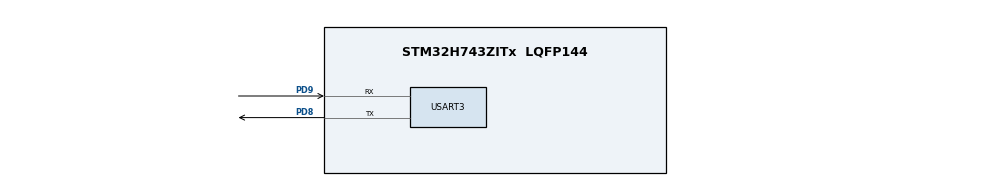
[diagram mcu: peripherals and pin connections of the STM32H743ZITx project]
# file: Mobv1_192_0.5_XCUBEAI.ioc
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CORTEX_M7.CPU_DCache=Enabled
CORTEX_M7.CPU_ICache=Enabled
Mcu.Family=STM32H7
Mcu.Name=STM32H743ZITx
Mcu.Package=LQFP144
NVIC.PriorityGroup=NVIC_PRIORITYGROUP_4
PD8.Mode=Asynchronous
PD8.Signal=USART3_TX
PD9.Mode=Asynchronous
PD9.Signal=USART3_RX
PH0-OSC_IN\ (PH0).Mode=HSE-External-Clock-Source
PH0-OSC_IN\ (PH0).Signal=RCC_OSC_IN
ProjectManager.HeapSize=0x800
ProjectManager.StackSize=0x800
ProjectManager.TargetToolchain=STM32CubeIDE
RCC.ADCFreq_Value=16125000
RCC.APB1CLKDivider=RCC_HCLK_DIV4
RCC.APB1Freq_Value=120000000
RCC.APB2CLKDivider=RCC_HCLK_DIV2
RCC.APB2Freq_Value=120000000
RCC.APB3Freq_Value=120000000
RCC.APB4Freq_Value=120000000
RCC.CortexFreq_Value=480000000
RCC.D1PPRE=RCC_APB3_DIV2
RCC.D2PPRE1=RCC_APB1_DIV2
RCC.D2PPRE2=RCC_APB2_DIV2
RCC.D3PPRE=RCC_APB4_DIV2
RCC.DIVM1=4
RCC.DIVN1=480
RCC.DIVQ1=20
RCC.HCLKFreq_Value=240000000
RCC.HPRE=RCC_HCLK_DIV2
RCC.HSE_VALUE=8000000
RCC.PLLFRACN=0
RCC.PLLM=25
RCC.PLLMUL=RCC_PLL_MUL9
RCC.PLLN=432
RCC.PLLQ=9
RCC.PLLSourceVirtual=RCC_PLLSOURCE_HSE
RCC.PRESCALERUSB=RCC_USBCLKSOURCE_PLL_DIV1_5
RCC.PWR_Regulator_Voltage_Scale=PWR_REGULATOR_VOLTAGE_SCALE0
RCC.SYSCLKFreq_VALUE=480000000
RCC.SYSCLKSource=RCC_SYSCLKSOURCE_PLLCLK
RCC.SYSCLKSourceVirtual=RCC_SYSCLKSOURCE_PLLCLK
RCC.USBFreq_Value=48000000
STMicroelectronics.X-CUBE-AI.7.1.0.ActivationBufferSizeList=426402
STMicroelectronics.X-CUBE-AI.7.1.0.ActivationBuffers=pool0
STMicroelectronics.X-CUBE-AI.7.1.0.ActivationNames=pool0
STMicroelectronics.X-CUBE-AI.7.1.0.ActivationSizes=AI_CNN_DATA_ACTIVATION_1_SIZE
STMicroelectronics.X-CUBE-AI.7.1.0.ApplicationCcDeviceJjApplication=SystemPerformance
STMicroelectronics.X-CUBE-AI.7.1.0.BSP.number=1
STMicroelectronics.X-CUBE-AI.7.1.0.HeapSize=0x800
STMicroelectronics.X-CUBE-AI.7.1.0.InternalRamActivationBufferMaxSize=AI_CNN_DATA_ACTIVATIONS_SIZE
STMicroelectronics.X-CUBE-AI.7.1.0.LatestDirectoryUsed-79d8653becbc10ded1216a368431f7b500d87fcf9e25c125302a12960ba76a4b=C\:\\Users\\ahmed\\Desktop\\STM\\Paper_02\\CMSIS\\workspace_ide\\Mobv1_192_0.5_XCUBEAI
STMicroelectronics.X-CUBE-AI.7.1.0.MaximumNumberOfInputLayer=1
STMicroelectronics.X-CUBE-AI.7.1.0.MaximumNumberOfOutputLayer=1
STMicroelectronics.X-CUBE-AI.7.1.0.MaximumSizeOfInputLayer=AI_CNN_IN_1_SIZE_BYTES
STMicroelectronics.X-CUBE-AI.7.1.0.MaximumSizeOfOutputLayer=AI_CNN_OUT_1_SIZE_BYTES
STMicroelectronics.X-CUBE-AI.7.1.0.ModelActualCompression-79d8653becbc10ded1216a368431f7b500d87fcf9e25c125302a12960ba76a4b=0.0
STMicroelectronics.X-CUBE-AI.7.1.0.ModelCompression-79d8653becbc10ded1216a368431f7b500d87fcf9e25c125302a12960ba76a4b=4
STMicroelectronics.X-CUBE-AI.7.1.0.ModelFlashOccupation-79d8653becbc10ded1216a368431f7b500d87fcf9e25c125302a12960ba76a4b=0
STMicroelectronics.X-CUBE-AI.7.1.0.ModelHashList=79d8653becbc10ded1216a368431f7b500d87fcf9e25c125302a12960ba76a4b
STMicroelectronics.X-CUBE-AI.7.1.0.ModelKind-79d8653becbc10ded1216a368431f7b500d87fcf9e25c125302a12960ba76a4b=TFLITE
STMicroelectronics.X-CUBE-AI.7.1.0.ModelMacc-79d8653becbc10ded1216a368431f7b500d87fcf9e25c125302a12960ba76a4b=110014868
STMicroelectronics.X-CUBE-AI.7.1.0.ModelName-79d8653becbc10ded1216a368431f7b500d87fcf9e25c125302a12960ba76a4b=cnn
STMicroelectronics.X-CUBE-AI.7.1.0.ModelNameList=cnn
STMicroelectronics.X-CUBE-AI.7.1.0.ModelRamOccupation-79d8653becbc10ded1216a368431f7b500d87fcf9e25c125302a12960ba76a4b=0
STMicroelectronics.X-CUBE-AI.7.1.0.ModelStructureFile-79d8653becbc10ded1216a368431f7b500d87fcf9e25c125302a12960ba76a4b=mobilenet_v1_0.5_192_quant.tflite
STMicroelectronics.X-CUBE-AI.7.1.0.ModelType-79d8653becbc10ded1216a368431f7b500d87fcf9e25c125302a12960ba76a4b=TFLite Micro runtime
STMicroelectronics.X-CUBE-AI.7.1.0.ReadyForCodeGeneration=true
STMicroelectronics.X-CUBE-AI.7.1.0.StackSize=0x800
STMicroelectronics.X-CUBE-AI.7.1.0.WorkingBufferStartAddrList=0xFFFFFFFF
STMicroelectronics.X-CUBE-AI.7.1.0.XAaCUBEAaAICcArtificialOoIntelligenceJjCore=true
STMicroelectronics.X-CUBE-AI.7.1.0.tfliteruntime=true
STMicroelectronics.X-CUBE-AI.7.1.00.BSP.STBoard=false
STMicroelectronics.X-CUBE-AI.7.1.00.BSP.api=Unknown
STMicroelectronics.X-CUBE-AI.7.1.00.BSP.condition=\!SEMDeviceJjApplicationJjApplicationTemplate
STMicroelectronics.X-CUBE-AI.7.1.00.BSP.i2caddr=0
STMicroelectronics.X-CUBE-AI.7.1.00.BSP.instance=USART3
STMicroelectronics.X-CUBE-AI.7.1.00.BSP.ip=USART
STMicroelectronics.X-CUBE-AI.7.1.00.BSP.mode=Asynchronous
STMicroelectronics.X-CUBE-AI.7.1.00.BSP.name=COM Port
STMicroelectronics.X-CUBE-AI.7.1.00.BSP.solution=USART3
USART3.VirtualMode-Asynchronous=VM_ASYNC
VP_CRC_VS_CRC.Mode=CRC_Activate
VP_STMicroelectronics.X-CUBE-AI_VS_ArtificialOoIntelligenceJjXAaCUBEAaAI_7.1.0.Mode=ArtificialOoIntelligenceJjXAaCUBEAaAI
VP_STMicroelectronics.X-CUBE-AI_VS_DeviceJjApplication_7.1.0.Mode=DeviceJjApplication
board=custom

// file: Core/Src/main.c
/* USER CODE BEGIN Header */
/**
  ******************************************************************************
  * @file           : main.c
  * @brief          : Main program body
  ******************************************************************************
  * @attention
  *
  * Copyright (c) 2022 STMicroelectronics.
  * All rights reserved.
  *
  * This software is licensed under terms that can be found in the LICENSE file
  * in the root directory of this software component.
  * If no LICENSE file comes with this software, it is provided AS-IS.
  *
  ******************************************************************************
  */
/* USER CODE END Header */
#include "main.h"
#include "app_x-cube-ai.h"

CRC_HandleTypeDef hcrc;

UART_HandleTypeDef huart3;

void SystemClock_Config(void);
static void MX_GPIO_Init(void);
static void MX_CRC_Init(void);
static void MX_USART3_UART_Init(void);

int main(void)
{

  /* Enable I-Cache---------------------------------------------------------*/
  SCB_EnableICache();

  /* Enable D-Cache---------------------------------------------------------*/
  SCB_EnableDCache();

  /* MCU Configuration--------------------------------------------------------*/

  /* Reset of all peripherals, Initializes the Flash interface and the Systick. */
  HAL_Init();

  /* Configure the system clock */
  SystemClock_Config();

  /* Initialize all configured peripherals */
  MX_GPIO_Init();
  MX_CRC_Init();
  MX_USART3_UART_Init();
  MX_X_CUBE_AI_Init();
  /* USER CODE BEGIN 2 */

  /* fill a float array with random data in the range [-1, 1] */

  /* USER CODE END 2 */

  /* Infinite loop */
  while (1)
  {

  MX_X_CUBE_AI_Process();
  }
}

void SystemClock_Config(void)
{
  RCC_OscInitTypeDef RCC_OscInitStruct = {0};
  RCC_ClkInitTypeDef RCC_ClkInitStruct = {0};

  /** Supply configuration update enable
  */
  HAL_PWREx_ConfigSupply(PWR_LDO_SUPPLY);
  /** Configure the main internal regulator output voltage
  */
  __HAL_PWR_VOLTAGESCALING_CONFIG(PWR_REGULATOR_VOLTAGE_SCALE0);

  while(!__HAL_PWR_GET_FLAG(PWR_FLAG_VOSRDY)) {}
  /** Initializes the RCC Oscillators according to the specified parameters
  * in the RCC_OscInitTypeDef structure.
  */
  RCC_OscInitStruct.OscillatorType = RCC_OSCILLATORTYPE_HSE;
  RCC_OscInitStruct.HSEState = RCC_HSE_BYPASS;
  RCC_OscInitStruct.PLL.PLLState = RCC_PLL_ON;
  RCC_OscInitStruct.PLL.PLLSource = RCC_PLLSOURCE_HSE;
  RCC_OscInitStruct.PLL.PLLM = 4;
  RCC_OscInitStruct.PLL.PLLN = 480;
  RCC_OscInitStruct.PLL.PLLP = 2;
  RCC_OscInitStruct.PLL.PLLQ = 20;
  RCC_OscInitStruct.PLL.PLLR = 2;
  RCC_OscInitStruct.PLL.PLLRGE = RCC_PLL1VCIRANGE_1;
  RCC_OscInitStruct.PLL.PLLVCOSEL = RCC_PLL1VCOWIDE;
  RCC_OscInitStruct.PLL.PLLFRACN = 0;
  if (HAL_RCC_OscConfig(&RCC_OscInitStruct) != HAL_OK)
  {
    Error_Handler();
  }
  /** Initializes the CPU, AHB and APB buses clocks
  */
  RCC_ClkInitStruct.ClockType = RCC_CLOCKTYPE_HCLK|RCC_CLOCKTYPE_SYSCLK
                              |RCC_CLOCKTYPE_PCLK1|RCC_CLOCKTYPE_PCLK2
                              |RCC_CLOCKTYPE_D3PCLK1|RCC_CLOCKTYPE_D1PCLK1;
  RCC_ClkInitStruct.SYSCLKSource = RCC_SYSCLKSOURCE_PLLCLK;
  RCC_ClkInitStruct.SYSCLKDivider = RCC_SYSCLK_DIV1;
  RCC_ClkInitStruct.AHBCLKDivider = RCC_HCLK_DIV2;
  RCC_ClkInitStruct.APB3CLKDivider = RCC_APB3_DIV2;
  RCC_ClkInitStruct.APB1CLKDivider = RCC_APB1_DIV2;
  RCC_ClkInitStruct.APB2CLKDivider = RCC_APB2_DIV2;
  RCC_ClkInitStruct.APB4CLKDivider = RCC_APB4_DIV2;

  if (HAL_RCC_ClockConfig(&RCC_ClkInitStruct, FLASH_LATENCY_4) != HAL_OK)
  {
    Error_Handler();
  }
}

static void MX_CRC_Init(void)
{

  hcrc.Instance = CRC;
  hcrc.Init.DefaultPolynomialUse = DEFAULT_POLYNOMIAL_ENABLE;
  hcrc.Init.DefaultInitValueUse = DEFAULT_INIT_VALUE_ENABLE;
  hcrc.Init.InputDataInversionMode = CRC_INPUTDATA_INVERSION_NONE;
  hcrc.Init.OutputDataInversionMode = CRC_OUTPUTDATA_INVERSION_DISABLE;
  hcrc.InputDataFormat = CRC_INPUTDATA_FORMAT_BYTES;
  if (HAL_CRC_Init(&hcrc) != HAL_OK)
  {
    Error_Handler();
  }

}

static void MX_USART3_UART_Init(void)
{

  huart3.Instance = USART3;
  huart3.Init.BaudRate = 115200;
  huart3.Init.WordLength = UART_WORDLENGTH_8B;
  huart3.Init.StopBits = UART_STOPBITS_1;
  huart3.Init.Parity = UART_PARITY_NONE;
  huart3.Init.Mode = UART_MODE_TX_RX;
  huart3.Init.HwFlowCtl = UART_HWCONTROL_NONE;
  huart3.Init.OverSampling = UART_OVERSAMPLING_16;
  huart3.Init.OneBitSampling = UART_ONE_BIT_SAMPLE_DISABLE;
  huart3.Init.ClockPrescaler = UART_PRESCALER_DIV1;
  huart3.AdvancedInit.AdvFeatureInit = UART_ADVFEATURE_NO_INIT;
  if (HAL_UART_Init(&huart3) != HAL_OK)
  {
    Error_Handler();
  }
  if (HAL_UARTEx_SetTxFifoThreshold(&huart3, UART_TXFIFO_THRESHOLD_1_8) != HAL_OK)
  {
    Error_Handler();
  }
  if (HAL_UARTEx_SetRxFifoThreshold(&huart3, UART_RXFIFO_THRESHOLD_1_8) != HAL_OK)
  {
    Error_Handler();
  }
  if (HAL_UARTEx_DisableFifoMode(&huart3) != HAL_OK)
  {
    Error_Handler();
  }

}

static void MX_GPIO_Init(void)
{

  /* GPIO Ports Clock Enable */
  __HAL_RCC_GPIOH_CLK_ENABLE();
  __HAL_RCC_GPIOD_CLK_ENABLE();

}

void Error_Handler(void)
{
  __disable_irq();
  while (1)
  {
  }
}
